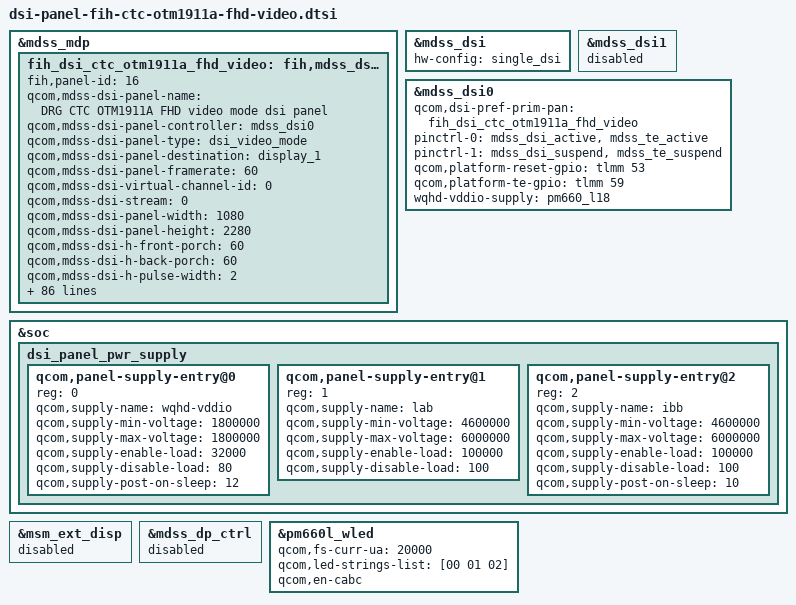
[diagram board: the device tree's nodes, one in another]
/* Copyright (c) 2013, The Linux Foundation. All rights reserved.
 *
 * This program is free software; you can redistribute it and/or modify
 * it under the terms of the GNU General Public License version 2 and
 * only version 2 as published by the Free Software Foundation.
 *
 * This program is distributed in the hope that it will be useful,
 * but WITHOUT ANY WARRANTY; without even the implied warranty of
 * MERCHANTABILITY or FITNESS FOR A PARTICULAR PURPOSE.  See the
 * GNU General Public License for more details.
 */

/*---------------------------------------------------------------------------
 * This file is autogenerated file using gcdb parser. Please do not edit it.
 * Update input XML file to add a new entry or update variable in this file
 * VERSION = "1.0"
 *---------------------------------------------------------------------------*/
&mdss_mdp {
	fih_dsi_ctc_otm1911a_fhd_video: fih,mdss_dsi_ctc_otm1911a_fhd_video {
		fih,panel-id = <16>;
		qcom,mdss-dsi-panel-name = "DRG CTC OTM1911A FHD video mode dsi panel";
		qcom,mdss-dsi-panel-controller = <&mdss_dsi0>;
		qcom,mdss-dsi-panel-type = "dsi_video_mode";
		qcom,mdss-dsi-panel-destination = "display_1";
		qcom,mdss-dsi-panel-framerate = <60>;
		qcom,mdss-dsi-virtual-channel-id = <0>;
		qcom,mdss-dsi-stream = <0>;
		qcom,mdss-dsi-panel-width = <1080>;
		qcom,mdss-dsi-panel-height = <2280>;
		qcom,mdss-dsi-h-front-porch = <60>;
		qcom,mdss-dsi-h-back-porch = <60>;
		qcom,mdss-dsi-h-pulse-width = <2>;
		qcom,mdss-dsi-h-sync-skew = <0>;
		qcom,mdss-dsi-v-front-porch = <16>;
		qcom,mdss-dsi-v-back-porch = <16>;
		qcom,mdss-dsi-v-pulse-width = <2>;
		qcom,mdss-dsi-h-left-border = <0>;
		qcom,mdss-dsi-h-right-border = <0>;
		qcom,mdss-dsi-v-top-border = <0>;
		qcom,mdss-dsi-v-bottom-border = <0>;
		qcom,mdss-dsi-bpp = <24>;
		qcom,mdss-dsi-color-order = "rgb_swap_rgb";
		qcom,mdss-dsi-underflow-color = <0xff>;
		qcom,mdss-dsi-border-color = <0>;
		
		qcom,mdss-dsi-on-command = [
			39 01 00 00 00 00 02 00 00
			39 01 00 00 00 00 04 FF 19 11 01
			39 01 00 00 00 00 02 00 80
			39 01 00 00 00 00 03 FF 19 11
			39 01 00 00 00 00 02 00 B0
			39 01 00 00 00 00 05 B3 04 38 08 E8
			05 01 00 00 78 00 02 11 00
			05 01 00 00 00 00 02 29 00
			05 01 00 00 0A 00 02 35 00
			39 01 00 00 00 00 03 51 FF 0F
			15 01 00 00 00 00 02 53 2C			
		];
		
		qcom,mdss-dsi-off-command = [
			05 01 00 00 0A 00 02 28 00
			05 01 00 00 96 00 02 10 00
		];
		
		qcom,mdss-dsi-on-command-state = "dsi_lp_mode";
		qcom,mdss-dsi-off-command-state = "dsi_hs_mode";
		qcom,mdss-dsi-h-sync-pulse = <0>;
		qcom,mdss-dsi-traffic-mode = "burst_mode";
		qcom,mdss-dsi-lane-map = "lane_map_0123";
		qcom,mdss-dsi-bllp-eof-power-mode;
		qcom,mdss-dsi-bllp-power-mode;
		qcom,mdss-dsi-lp11-init;
		qcom,mdss-dsi-init-delay-us = <5>;
		qcom,mdss-dsi-lane-0-state;
		qcom,mdss-dsi-lane-1-state;
		qcom,mdss-dsi-lane-2-state;
		qcom,mdss-dsi-lane-3-state;
		qcom,mdss-dsi-t-clk-post = <0x0D>;
		qcom,mdss-dsi-t-clk-pre = <0x32>;
		qcom,mdss-dsi-dma-trigger = "trigger_sw";
		qcom,mdss-dsi-mdp-trigger = "none";
		qcom,mdss-dsi-reset-sequence = <1 10>, <0 5>, <1 15>;

		qcom,mdss-pan-physical-width-dimension = <63>;
		qcom,mdss-pan-physical-height-dimension = <134>;
		qcom,mdss-pan-physical-width-dimension-full = <6350>;
		qcom,mdss-pan-physical-height-dimension-full = <13406>;

		qcom,suspend-ulps-enabled;
		
		/* SW4-HL-Display-EliminateMostDsiError-00+{_20170216 */
		qcom,mdss-dsi-tx-eot-append;
		/* SW4-HL-Display-EliminateMostDsiError-00+}_20170216 */

		/* SW4-HL-Display-DynamicReadWriteRegister-00+{_20160729 */
		fih,mdss-dsi-write-reg-command = [
			39 01 00 00 00 00 04 FF 78 07 00
		];

		fih,mdss-dsi-write-reg-command-state = "dsi_lp_mode";
		/* SW4-HL-Display-DynamicReadWriteRegister-00+}_20160729 */

		/* TBD */
		/* B2N - gatycclu - Enable ESD check */
		/* 
		qcom,esd-check-enabled;
		qcom,mdss-dsi-panel-status-check-mode = "reg_read";
		qcom,mdss-dsi-panel-status-command = [06 01 00 01 00 00 01 0a
			06 01 00 01 00 00 01 0d
			06 01 00 01 00 00 01 ac];
		qcom,mdss-dsi-panel-status-command-state = "dsi_hs_mode";
		qcom,mdss-dsi-panel-status-value = <0x9c>,<0x00>,<0x00>;
		qcom,mdss-dsi-panel-on-check-value = <0x9c>,<0x00>,<0x00>;
		qcom,mdss-dsi-panel-status-read-length = <1>,<1>,<1>;
		qcom,mdss-dsi-panel-max-error-count = <3>;
		*/
		/* end - B2N - Enable ESD check */
		
		qcom,mdss-dsi-cabc-off-command = [
			39 01 00 00 00 00 02 55 00
		];

		qcom,mdss-dsi-cabc-ui-command = [
			39 01 00 00 00 00 02 55 01
		];

		qcom,mdss-dsi-cabc-still-command = [
			39 01 00 00 00 00 02 55 02
		];

		qcom,mdss-dsi-cabc-moving-command = [
			39 01 00 00 00 00 02 55 03
		];

		qcom,mdss-dsi-cabc-off-command-state = "dsi_hs_mode";
		qcom,mdss-dsi-cabc-ui-command-state = "dsi_hs_mode";
		qcom,mdss-dsi-cabc-still-command-state = "dsi_hs_mode";
		qcom,mdss-dsi-cabc-moving-command-state = "dsi_hs_mode";

		qcom,mdss-dsi-cabc-off-command-BeforeInit = [
			39 01 00 00 00 00 02 55 00
		];

		qcom,mdss-dsi-cabc-ui-command-BeforeInit = [
			39 01 00 00 00 00 02 55 01
		];

		qcom,mdss-dsi-cabc-still-command-BeforeInit = [
			39 01 00 00 00 00 02 55 02
		];

		qcom,mdss-dsi-cabc-moving-command-BeforeInit = [
			39 01 00 00 00 00 02 55 03
		];

		qcom,mdss-dsi-cabc-off-command-BeforeInit-state = "dsi_lp_mode";
		qcom,mdss-dsi-cabc-ui-command-BeforeInit-state = "dsi_lp_mode";
		qcom,mdss-dsi-cabc-still-command-BeforeInit-state = "dsi_lp_mode";
		qcom,mdss-dsi-cabc-moving-command-BeforeInit-state = "dsi_lp_mode";

		//fih,default-cabc-mode = <2>;
	};
};

&fih_dsi_ctc_otm1911a_fhd_video {
	qcom,mdss-dsi-panel-timings-phy-v2 = [
		25 20 09 0A 06 03 04 a0
		25 20 09 0A 06 03 04 a0
		25 20 09 0A 06 03 04 a0
		25 20 09 0A 06 03 04 a0
		25 20 09 0A 06 03 04 a0
	];
	qcom,mdss-dsi-bl-pmic-control-type = "bl_ctrl_wled";
	qcom,mdss-dsi-bl-min-level = <1>;
	qcom,mdss-dsi-bl-max-level = <4095>;
	qcom,panel-supply-entries = <&dsi_panel_pwr_supply>;
};

&mdss_dsi {
	hw-config = "single_dsi";
};

/* TBD */
/*
&mdss_dsi0_pll {
	qcom,ssc-frequency-hz = <30000>;
	qcom,ssc-ppm = <5000>;
};
*/

&mdss_dsi1 {
	status = "disabled";
};


&mdss_dsi0 {
	qcom,dsi-pref-prim-pan = <&fih_dsi_ctc_otm1911a_fhd_video>;
	pinctrl-names = "mdss_default", "mdss_sleep";
	pinctrl-0 = <&mdss_dsi_active &mdss_te_active>;
	pinctrl-1 = <&mdss_dsi_suspend &mdss_te_suspend>;
	qcom,platform-reset-gpio = <&tlmm 53 0>;
	qcom,platform-te-gpio = <&tlmm 59 0>;
        wqhd-vddio-supply = <&pm660_l18>;
};

&soc {
	/delete-node/dsi_panel_pwr_supply;

	dsi_panel_pwr_supply: dsi_panel_pwr_supply {
		#address-cells = <1>;
		#size-cells = <0>;

		/* PM660 L18A */
		qcom,panel-supply-entry@0 {
			reg = <0>;
			qcom,supply-name = "wqhd-vddio";
			qcom,supply-min-voltage = <1800000>;
			qcom,supply-max-voltage = <1800000>;
			qcom,supply-enable-load = <32000>;
			qcom,supply-disable-load = <80>;
			qcom,supply-post-on-sleep = <12>;
		};

		qcom,panel-supply-entry@1 {
			reg = <1>;
			qcom,supply-name = "lab";
			qcom,supply-min-voltage = <4600000>;
			qcom,supply-max-voltage = <6000000>;
			qcom,supply-enable-load = <100000>;
			qcom,supply-disable-load = <100>;
		};

		qcom,panel-supply-entry@2 {
			reg = <2>;
			qcom,supply-name = "ibb";
			qcom,supply-min-voltage = <4600000>;
			qcom,supply-max-voltage = <6000000>;
			qcom,supply-enable-load = <100000>;
			qcom,supply-disable-load = <100>;
			qcom,supply-post-on-sleep = <10>;
		};		
	};
};

&msm_ext_disp {
	status = "disabled";
};

&mdss_dp_ctrl {
	status = "disabled";
};

&pm660l_wled {
	qcom,fs-curr-ua = <20000>;
	qcom,led-strings-list = [00 01 02];	/* 5S3P  */
	/* TBD */
	qcom,en-cabc;	/* SW4-HL-Display-ImplementCECTCABC-00+_20160126 */
};

